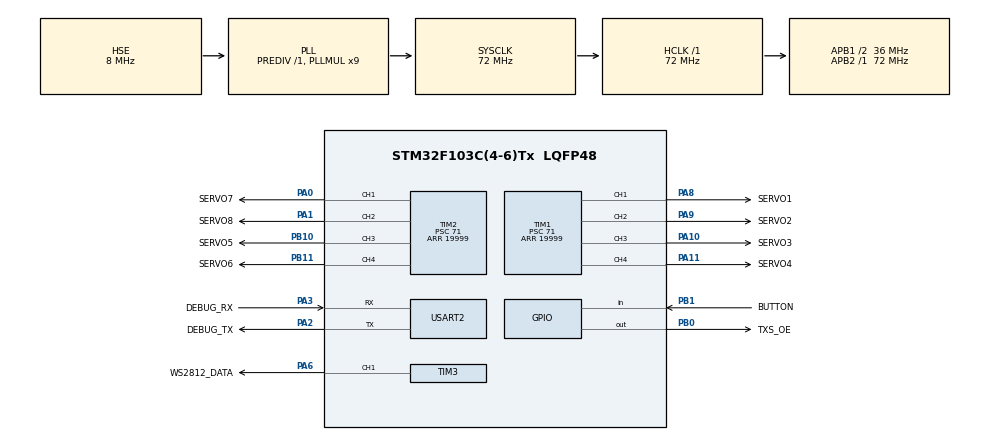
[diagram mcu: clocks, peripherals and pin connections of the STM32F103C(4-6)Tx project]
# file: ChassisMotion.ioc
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Dma.Request0=TIM3_CH1/TRIG
Dma.TIM3_CH1/TRIG.0.Direction=DMA_MEMORY_TO_PERIPH
Dma.TIM3_CH1/TRIG.0.Instance=DMA1_Channel6
Dma.TIM3_CH1/TRIG.0.MemDataAlignment=DMA_MDATAALIGN_HALFWORD
Dma.TIM3_CH1/TRIG.0.MemInc=DMA_MINC_ENABLE
Dma.TIM3_CH1/TRIG.0.Mode=DMA_CIRCULAR
Dma.TIM3_CH1/TRIG.0.PeriphDataAlignment=DMA_PDATAALIGN_HALFWORD
Dma.TIM3_CH1/TRIG.0.PeriphInc=DMA_PINC_DISABLE
Dma.TIM3_CH1/TRIG.0.Priority=DMA_PRIORITY_HIGH
Mcu.Family=STM32F1
Mcu.Name=STM32F103C(4-6)Tx
Mcu.Package=LQFP48
NVIC.DMA1_Channel6_IRQn=true\:1\:0\:true\:false\:true\:false\:true\:true
NVIC.PriorityGroup=NVIC_PRIORITYGROUP_4
NVIC.USART2_IRQn=true\:8\:0\:true\:false\:true\:true\:true\:true
PA0-WKUP.GPIO_Label=SERVO7
PA0-WKUP.Signal=S_TIM2_CH1_ETR
PA1.GPIO_Label=SERVO8
PA1.Signal=S_TIM2_CH2
PA10.GPIO_Label=SERVO3
PA10.Signal=S_TIM1_CH3
PA11.GPIO_Label=SERVO4
PA11.Signal=S_TIM1_CH4
PA13.Mode=Serial_Wire
PA13.Signal=SYS_JTMS-SWDIO
PA14.Mode=Serial_Wire
PA14.Signal=SYS_JTCK-SWCLK
PA2.GPIO_Label=DEBUG_TX
PA2.Mode=Asynchronous
PA2.Signal=USART2_TX
PA3.GPIO_Label=DEBUG_RX
PA3.Mode=Asynchronous
PA3.Signal=USART2_RX
PA6.GPIO_Label=WS2812_DATA
PA6.GPIO_Speed=GPIO_SPEED_FREQ_HIGH
PA6.Signal=S_TIM3_CH1
PA8.GPIO_Label=SERVO1
PA8.Signal=S_TIM1_CH1
PA9.GPIO_Label=SERVO2
PA9.Signal=S_TIM1_CH2
PB0.GPIO_Label=TXS_OE
PB0.Signal=GPIO_Output
PB1.GPIO_Label=BUTTON
PB1.GPIO_PuPd=GPIO_PULLUP
PB1.Signal=GPIO_Input
PB10.GPIO_Label=SERVO5
PB10.Signal=S_TIM2_CH3
PB11.GPIO_Label=SERVO6
PB11.Signal=S_TIM2_CH4
PD0-OSC_IN.Mode=HSE-External-Oscillator
PD0-OSC_IN.Signal=RCC_OSC_IN
PD1-OSC_OUT.Mode=HSE-External-Oscillator
PD1-OSC_OUT.Signal=RCC_OSC_OUT
ProjectManager.HeapSize=0x0
ProjectManager.StackSize=0x400
ProjectManager.TargetToolchain=MDK-ARM V5.32
RCC.AHBFreq_Value=72000000
RCC.APB1CLKDivider=RCC_HCLK_DIV2
RCC.APB1Freq_Value=36000000
RCC.APB1TimFreq_Value=72000000
RCC.APB2Freq_Value=72000000
RCC.APB2TimFreq_Value=72000000
RCC.HCLKFreq_Value=72000000
RCC.PLLMUL=RCC_PLL_MUL9
RCC.PLLSourceVirtual=RCC_PLLSOURCE_HSE
RCC.SYSCLKFreq_VALUE=72000000
RCC.SYSCLKSource=RCC_SYSCLKSOURCE_PLLCLK
RCC.USBFreq_Value=72000000
SH.S_TIM1_CH1.0=TIM1_CH1,PWM Generation1 CH1
SH.S_TIM1_CH2.0=TIM1_CH2,PWM Generation2 CH2
SH.S_TIM1_CH3.0=TIM1_CH3,PWM Generation3 CH3
SH.S_TIM1_CH4.0=TIM1_CH4,PWM Generation4 CH4
SH.S_TIM2_CH1_ETR.0=TIM2_CH1,PWM Generation1 CH1
SH.S_TIM2_CH2.0=TIM2_CH2,PWM Generation2 CH2
SH.S_TIM2_CH3.0=TIM2_CH3,PWM Generation3 CH3
SH.S_TIM2_CH4.0=TIM2_CH4,PWM Generation4 CH4
SH.S_TIM3_CH1.0=TIM3_CH1,PWM Generation1 CH1
TIM1.AutoReloadPreload=TIM_AUTORELOAD_PRELOAD_ENABLE
TIM1.Channel-PWM\ Generation1\ CH1=TIM_CHANNEL_1
TIM1.Channel-PWM\ Generation2\ CH2=TIM_CHANNEL_2
TIM1.Channel-PWM\ Generation3\ CH3=TIM_CHANNEL_3
TIM1.Channel-PWM\ Generation4\ CH4=TIM_CHANNEL_4
TIM1.Period=19999
TIM1.Prescaler=71
TIM1.Pulse-PWM\ Generation1\ CH1=1500
TIM1.Pulse-PWM\ Generation2\ CH2=1500
TIM1.Pulse-PWM\ Generation3\ CH3=1500
TIM1.Pulse-PWM\ Generation4\ CH4=1500
TIM2.AutoReloadPreload=TIM_AUTORELOAD_PRELOAD_ENABLE
TIM2.Channel-PWM\ Generation1\ CH1=TIM_CHANNEL_1
TIM2.Channel-PWM\ Generation2\ CH2=TIM_CHANNEL_2
TIM2.Channel-PWM\ Generation3\ CH3=TIM_CHANNEL_3
TIM2.Channel-PWM\ Generation4\ CH4=TIM_CHANNEL_4
TIM2.Period=19999
TIM2.Prescaler=71
TIM2.Pulse-PWM\ Generation1\ CH1=1500
TIM2.Pulse-PWM\ Generation2\ CH2=1500
TIM2.Pulse-PWM\ Generation3\ CH3=1500
TIM2.Pulse-PWM\ Generation4\ CH4=1500
TIM3.AutoReloadPreload=TIM_AUTORELOAD_PRELOAD_ENABLE
TIM3.Channel-PWM\ Generation1\ CH1=TIM_CHANNEL_1
TIM3.Period=89
USART2.VirtualMode=VM_ASYNC
VP_TIM1_VS_ClockSourceINT.Mode=Internal
VP_TIM2_VS_ClockSourceINT.Mode=Internal
board=custom

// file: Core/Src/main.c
/* USER CODE BEGIN Header */
/**
  ******************************************************************************
  * @file           : main.c
  * @brief          : Main program body
  ******************************************************************************
  * @attention
  *
  * Copyright (c) 2026 STMicroelectronics.
  * All rights reserved.
  *
  * This software is licensed under terms that can be found in the LICENSE file
  * in the root directory of this software component.
  * If no LICENSE file comes with this software, it is provided AS-IS.
  *
  ******************************************************************************
  */
/* USER CODE END Header */
#include "main.h"
#include "dma.h"
#include "tim.h"
#include "usart.h"
#include "gpio.h"

/* USER CODE BEGIN Includes */
#include "app.h"
/* USER CODE END Includes */

void SystemClock_Config(void);

int main(void)
{

  /* MCU Configuration--------------------------------------------------------*/

  /* Reset of all peripherals, Initializes the Flash interface and the Systick. */
  HAL_Init();

  /* Configure the system clock */
  SystemClock_Config();

  /* Initialize all configured peripherals */
  MX_GPIO_Init();
  MX_DMA_Init();
  MX_TIM1_Init();
  MX_TIM2_Init();
  MX_TIM3_Init();
  MX_USART2_UART_Init();
  /* USER CODE BEGIN 2 */
  if (!app_init()) Error_Handler();
  /* USER CODE END 2 */

  /* Infinite loop */
  while (1)
  {

    /* USER CODE BEGIN 3 */
    app_poll();
  }
  /* USER CODE END 3 */
}

void SystemClock_Config(void)
{
  RCC_OscInitTypeDef RCC_OscInitStruct = {0};
  RCC_ClkInitTypeDef RCC_ClkInitStruct = {0};

  /** Initializes the RCC Oscillators according to the specified parameters
  * in the RCC_OscInitTypeDef structure.
  */
  RCC_OscInitStruct.OscillatorType = RCC_OSCILLATORTYPE_HSE;
  RCC_OscInitStruct.HSEState = RCC_HSE_ON;
  RCC_OscInitStruct.HSEPredivValue = RCC_HSE_PREDIV_DIV1;
  RCC_OscInitStruct.HSIState = RCC_HSI_ON;
  RCC_OscInitStruct.PLL.PLLState = RCC_PLL_ON;
  RCC_OscInitStruct.PLL.PLLSource = RCC_PLLSOURCE_HSE;
  RCC_OscInitStruct.PLL.PLLMUL = RCC_PLL_MUL9;
  if (HAL_RCC_OscConfig(&RCC_OscInitStruct) != HAL_OK)
  {
    Error_Handler();
  }

  /** Initializes the CPU, AHB and APB buses clocks
  */
  RCC_ClkInitStruct.ClockType = RCC_CLOCKTYPE_HCLK|RCC_CLOCKTYPE_SYSCLK
                              |RCC_CLOCKTYPE_PCLK1|RCC_CLOCKTYPE_PCLK2;
  RCC_ClkInitStruct.SYSCLKSource = RCC_SYSCLKSOURCE_PLLCLK;
  RCC_ClkInitStruct.AHBCLKDivider = RCC_SYSCLK_DIV1;
  RCC_ClkInitStruct.APB1CLKDivider = RCC_HCLK_DIV2;
  RCC_ClkInitStruct.APB2CLKDivider = RCC_HCLK_DIV1;

  if (HAL_RCC_ClockConfig(&RCC_ClkInitStruct, FLASH_LATENCY_2) != HAL_OK)
  {
    Error_Handler();
  }
}

void Error_Handler(void)
{
  __disable_irq();
  while (1)
  {
  }
}
